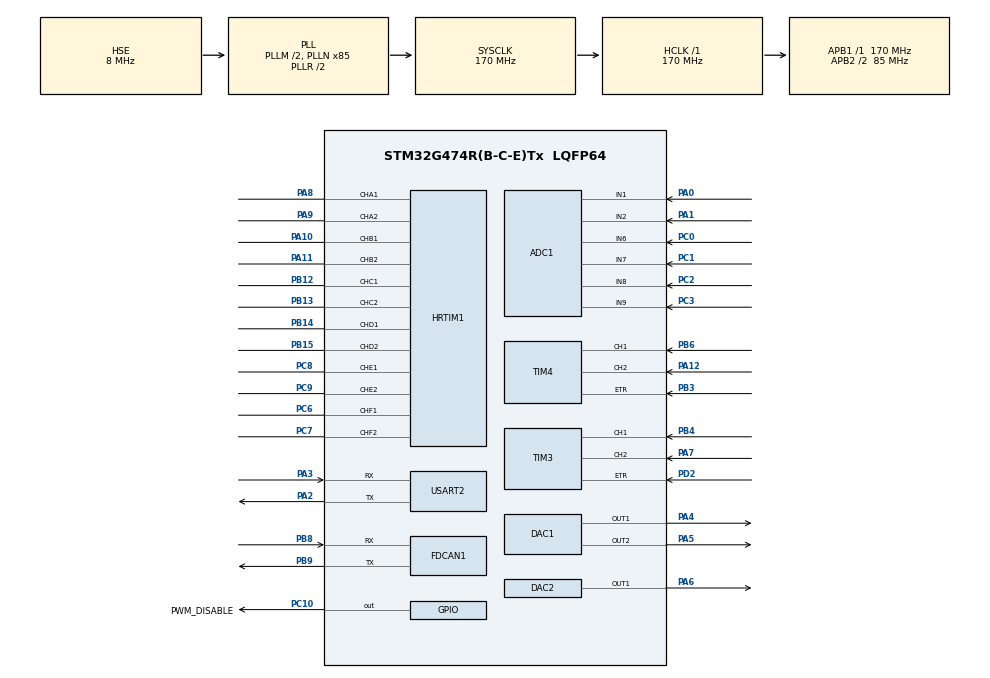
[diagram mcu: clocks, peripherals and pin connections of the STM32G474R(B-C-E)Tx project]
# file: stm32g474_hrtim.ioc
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ADC1.Channel-0\#ChannelRegularConversion=ADC_CHANNEL_6
ADC1.NbrOfConversionFlag=1
ADC1.OffsetNumber-0\#ChannelRegularConversion=ADC_OFFSET_NONE
ADC1.Rank-0\#ChannelRegularConversion=1
ADC1.SamplingTime-0\#ChannelRegularConversion=ADC_SAMPLETIME_2CYCLES_5
ADC1.SingleDiff-0\#ChannelRegularConversion=ADC_DIFFERENTIAL_ENDED
ADC1.master=1
DAC1.DAC_Channel-DAC_OUT2=DAC_CHANNEL_2
Dma.Request0=USART2_RX
Dma.USART2_RX.0.Direction=DMA_PERIPH_TO_MEMORY
Dma.USART2_RX.0.EventEnable=DISABLE
Dma.USART2_RX.0.Instance=DMA1_Channel2
Dma.USART2_RX.0.MemDataAlignment=DMA_MDATAALIGN_BYTE
Dma.USART2_RX.0.MemInc=DMA_MINC_ENABLE
Dma.USART2_RX.0.Mode=DMA_CIRCULAR
Dma.USART2_RX.0.PeriphDataAlignment=DMA_PDATAALIGN_BYTE
Dma.USART2_RX.0.PeriphInc=DMA_PINC_DISABLE
Dma.USART2_RX.0.Polarity=HAL_DMAMUX_REQ_GEN_RISING
Dma.USART2_RX.0.Priority=DMA_PRIORITY_LOW
Dma.USART2_RX.0.RequestNumber=1
Dma.USART2_RX.0.SignalID=NONE
Dma.USART2_RX.0.SyncEnable=DISABLE
Dma.USART2_RX.0.SyncPolarity=HAL_DMAMUX_SYNC_NO_EVENT
Dma.USART2_RX.0.SyncRequestNumber=1
Dma.USART2_RX.0.SyncSignalID=NONE
FDCAN1.CalculateBaudRateNominal=3541666
FDCAN1.CalculateTimeBitNominal=282
FDCAN1.CalculateTimeQuantumNominal=94.11764705882354
HRTIM1.ADCTrigger1_Source1=HRTIM_ADCTRIGGEREVENT13_TIMERA_PERIOD
HRTIM1.ADCTrigger_Id1=HRTIM_ADCTRIGGER_1
HRTIM1.CompareUnit1-Output_TA1TA2=HRTIM_COMPAREUNIT_1
HRTIM1.CompareValue1-Output_TA1TA2=17000
HRTIM1.DeadTimeInsertion-Output_TA1TA2=HRTIM_TIMDEADTIMEINSERTION_ENABLED
HRTIM1.Deadtimeconfig-Output_TA1TA2=HRTIM_TIMERINDEX_TIMER_A
HRTIM1.FallingValue-Output_TA1TA2=85
HRTIM1.NumberADCTriggerSource1=1
HRTIM1.NumberResetSource1-Output_TA1TA2=1
HRTIM1.NumberSetSource1-Output_TA1TA2=1
HRTIM1.Periode_TA=HRTIM_PERIOD
HRTIM1.PreloadEnable-Output_TA1TA2=HRTIM_PRELOAD_ENABLED
HRTIM1.PrescalerDead-Output_TA1TA2=HRTIM_TIMDEADTIME_PRESCALERRATIO_DIV1
HRTIM1.PrescalerRatio_TA=HRTIM_PRESCALERRATIO_MUL8
HRTIM1.ResetOutput1_Source1-Output_TA1TA2=HRTIM_OUTPUTRESET_TIMPER
HRTIM1.RisingValue-Output_TA1TA2=85
HRTIM1.SetOutput1_Source1-Output_TA1TA2=HRTIM_OUTPUTSET_TIMCMP1
HRTIM1.UpDownMode-Output_TA1TA2=HRTIM_TIMERUPDOWNMODE_UPDOWN
Mcu.Family=STM32G4
Mcu.Name=STM32G474R(B-C-E)Tx
Mcu.Package=LQFP64
Mcu.UserConstants=HRTIM_PERIOD,34000
NVIC.ADC1_2_IRQn=true\:0\:0\:false\:false\:true\:true\:true\:true
NVIC.DMA1_Channel2_IRQn=true\:1\:0\:false\:false\:true\:false\:true\:true
NVIC.PriorityGroup=NVIC_PRIORITYGROUP_4
NVIC.USART2_IRQn=true\:1\:0\:false\:false\:true\:true\:true\:true
PA0.Mode=IN1-Differential
PA0.Signal=ADC1_IN1
PA1.Mode=IN1-Differential
PA1.Signal=ADC1_IN2
PA10.Mode=Output_TB1TB2
PA10.Signal=HRTIM1_CHB1
PA11.Mode=Output_TB1TB2
PA11.Signal=HRTIM1_CHB2
PA12.Signal=S_TIM4_CH2
PA13.Mode=Serial_Wire
PA13.Signal=SYS_JTMS-SWDIO
PA14.Mode=Serial_Wire
PA14.Signal=SYS_JTCK-SWCLK
PA2.Mode=Asynchronous
PA2.Signal=USART2_TX
PA3.Mode=Asynchronous
PA3.Signal=USART2_RX
PA4.Signal=COMP_DAC11_group
PA5.Signal=COMP_DAC12_group
PA6.Signal=COMP_DAC21_group
PA7.Signal=S_TIM3_CH2
PA8.Mode=Output_TA1TA2
PA8.Signal=HRTIM1_CHA1
PA9.Mode=Output_TA1TA2
PA9.Signal=HRTIM1_CHA2
PB12.Mode=Output_TC1TC2
PB12.Signal=HRTIM1_CHC1
PB13.Mode=Output_TC1TC2
PB13.Signal=HRTIM1_CHC2
PB14.Mode=Output_TD1TD2
PB14.Signal=HRTIM1_CHD1
PB15.Mode=Output_TD1TD2
PB15.Signal=HRTIM1_CHD2
PB3.Signal=S_TIM4_ETR
PB4.Signal=S_TIM3_CH1
PB6.Signal=S_TIM4_CH1
PB8-BOOT0.Mode=FDCAN_Activate
PB8-BOOT0.Signal=FDCAN1_RX
PB9.Mode=FDCAN_Activate
PB9.Signal=FDCAN1_TX
PC0.Mode=IN6-Differential
PC0.Signal=ADC1_IN6
PC1.Mode=IN6-Differential
PC1.Signal=ADC1_IN7
PC10.GPIO_Label=PWM_DISABLE
PC10.Signal=GPIO_Output
PC14-OSC32_IN.Mode=LSE-External-Oscillator
PC14-OSC32_IN.Signal=RCC_OSC32_IN
PC15-OSC32_OUT.Mode=LSE-External-Oscillator
PC15-OSC32_OUT.Signal=RCC_OSC32_OUT
PC2.Mode=IN8-Differential
PC2.Signal=ADC1_IN8
PC3.Mode=IN8-Differential
PC3.Signal=ADC1_IN9
PC6.Mode=Output_TF1TF2
PC6.Signal=HRTIM1_CHF1
PC7.Mode=Output_TF1TF2
PC7.Signal=HRTIM1_CHF2
PC8.Mode=Output_TE1TE2
PC8.Signal=HRTIM1_CHE1
PC9.Mode=Output_TE1TE2
PC9.Signal=HRTIM1_CHE2
PD2.Signal=S_TIM3_ETR
PF0-OSC_IN.Mode=HSE-External-Oscillator
PF0-OSC_IN.Signal=RCC_OSC_IN
PF1-OSC_OUT.Mode=HSE-External-Oscillator
PF1-OSC_OUT.Signal=RCC_OSC_OUT
ProjectManager.HeapSize=0x200
ProjectManager.StackSize=0x400
ProjectManager.TargetToolchain=MDK-ARM V5.32
RCC.ADC12Freq_Value=170000000
RCC.ADC345Freq_Value=170000000
RCC.AHBFreq_Value=170000000
RCC.APB1Freq_Value=170000000
RCC.APB1TimFreq_Value=170000000
RCC.APB2CLKDivider=RCC_HCLK_DIV2
RCC.APB2Freq_Value=85000000
RCC.APB2TimFreq_Value=170000000
RCC.CortexFreq_Value=170000000
RCC.EXTERNAL_CLOCK_VALUE=12288000
RCC.HCLKFreq_Value=170000000
RCC.HSE_VALUE=8000000
RCC.HSI48_VALUE=48000000
RCC.HSI_VALUE=16000000
RCC.PLLM=RCC_PLLM_DIV2
RCC.PLLN=85
RCC.PLLSourceVirtual=RCC_PLLSOURCE_HSE
RCC.SYSCLKFreq_VALUE=170000000
RCC.SYSCLKSource=RCC_SYSCLKSOURCE_PLLCLK
RCC.USBFreq_Value=170000000
RCC.VCOOutputFreq_Value=340000000
SH.COMP_DAC11_group.0=DAC1_OUT1,DAC_OUT1
SH.COMP_DAC12_group.0=DAC1_OUT2,DAC_OUT2
SH.COMP_DAC21_group.0=DAC2_OUT1,DAC_OUT1
SH.S_TIM3_CH1.0=TIM3_CH1,Encoder_Interface_w_index
SH.S_TIM3_CH2.0=TIM3_CH2,Encoder_Interface_w_index
SH.S_TIM3_ETR.0=TIM3_ETR,Encoder_Interface_w_index
SH.S_TIM4_CH1.0=TIM4_CH1,Encoder_Interface_w_index
SH.S_TIM4_CH2.0=TIM4_CH2,Encoder_Interface_w_index
SH.S_TIM4_ETR.0=TIM4_ETR,Encoder_Interface_w_index
USART2.VirtualMode-Asynchronous=VM_ASYNC
VP_SYS_VS_DBSignals.Mode=DisableDeadBatterySignals
board=custom

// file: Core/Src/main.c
/* USER CODE BEGIN Header */
/**
  ******************************************************************************
  * @file           : main.c
  * @brief          : Main program body
  ******************************************************************************
  * @attention
  *
  * Copyright (c) 2026 STMicroelectronics.
  * All rights reserved.
  *
  * This software is licensed under terms that can be found in the LICENSE file
  * in the root directory of this software component.
  * If no LICENSE file comes with this software, it is provided AS-IS.
  *
  ******************************************************************************
  */
/* USER CODE END Header */
#include "main.h"

/* USER CODE BEGIN Includes */
#include<gmp_core.h>
/* USER CODE END Includes */

ADC_HandleTypeDef hadc1;

DAC_HandleTypeDef hdac1;
DAC_HandleTypeDef hdac2;

FDCAN_HandleTypeDef hfdcan1;

HRTIM_HandleTypeDef hhrtim1;

TIM_HandleTypeDef htim3;
TIM_HandleTypeDef htim4;

UART_HandleTypeDef huart2;
DMA_HandleTypeDef hdma_usart2_rx;

void SystemClock_Config(void);
static void MX_GPIO_Init(void);
static void MX_DAC1_Init(void);
static void MX_DAC2_Init(void);
static void MX_FDCAN1_Init(void);
static void MX_HRTIM1_Init(void);
static void MX_TIM3_Init(void);
static void MX_TIM4_Init(void);
static void MX_USART2_UART_Init(void);
static void MX_ADC1_Init(void);

int main(void)
{

  /* MCU Configuration--------------------------------------------------------*/

  /* Reset of all peripherals, Initializes the Flash interface and the Systick. */
  HAL_Init();

  /* Configure the system clock */
  SystemClock_Config();

  /* Initialize all configured peripherals */
  MX_GPIO_Init();
  MX_DAC1_Init();
  MX_DAC2_Init();
  MX_FDCAN1_Init();
  MX_HRTIM1_Init();
  MX_TIM3_Init();
  MX_TIM4_Init();
  MX_USART2_UART_Init();
  MX_ADC1_Init();

  /* Infinite loop */
  while (1)
  {

  }
}

void SystemClock_Config(void)
{
  RCC_OscInitTypeDef RCC_OscInitStruct = {0};
  RCC_ClkInitTypeDef RCC_ClkInitStruct = {0};

  /** Configure the main internal regulator output voltage
  */
  HAL_PWREx_ControlVoltageScaling(PWR_REGULATOR_VOLTAGE_SCALE1_BOOST);

  /** Initializes the RCC Oscillators according to the specified parameters
  * in the RCC_OscInitTypeDef structure.
  */
  RCC_OscInitStruct.OscillatorType = RCC_OSCILLATORTYPE_HSE;
  RCC_OscInitStruct.HSEState = RCC_HSE_ON;
  RCC_OscInitStruct.PLL.PLLState = RCC_PLL_ON;
  RCC_OscInitStruct.PLL.PLLSource = RCC_PLLSOURCE_HSE;
  RCC_OscInitStruct.PLL.PLLM = RCC_PLLM_DIV2;
  RCC_OscInitStruct.PLL.PLLN = 85;
  RCC_OscInitStruct.PLL.PLLP = RCC_PLLP_DIV2;
  RCC_OscInitStruct.PLL.PLLQ = RCC_PLLQ_DIV2;
  RCC_OscInitStruct.PLL.PLLR = RCC_PLLR_DIV2;
  if (HAL_RCC_OscConfig(&RCC_OscInitStruct) != HAL_OK)
  {
    Error_Handler();
  }

  /** Initializes the CPU, AHB and APB buses clocks
  */
  RCC_ClkInitStruct.ClockType = RCC_CLOCKTYPE_HCLK|RCC_CLOCKTYPE_SYSCLK
                              |RCC_CLOCKTYPE_PCLK1|RCC_CLOCKTYPE_PCLK2;
  RCC_ClkInitStruct.SYSCLKSource = RCC_SYSCLKSOURCE_PLLCLK;
  RCC_ClkInitStruct.AHBCLKDivider = RCC_SYSCLK_DIV1;
  RCC_ClkInitStruct.APB1CLKDivider = RCC_HCLK_DIV1;
  RCC_ClkInitStruct.APB2CLKDivider = RCC_HCLK_DIV2;

  if (HAL_RCC_ClockConfig(&RCC_ClkInitStruct, FLASH_LATENCY_4) != HAL_OK)
  {
    Error_Handler();
  }
}

static void MX_ADC1_Init(void)
{

  ADC_MultiModeTypeDef multimode = {0};
  ADC_ChannelConfTypeDef sConfig = {0};

  /** Common config
  */
  hadc1.Instance = ADC1;
  hadc1.Init.ClockPrescaler = ADC_CLOCK_SYNC_PCLK_DIV4;
  hadc1.Init.Resolution = ADC_RESOLUTION_12B;
  hadc1.Init.DataAlign = ADC_DATAALIGN_RIGHT;
  hadc1.Init.GainCompensation = 0;
  hadc1.Init.ScanConvMode = ADC_SCAN_DISABLE;
  hadc1.Init.EOCSelection = ADC_EOC_SINGLE_CONV;
  hadc1.Init.LowPowerAutoWait = DISABLE;
  hadc1.Init.ContinuousConvMode = DISABLE;
  hadc1.Init.NbrOfConversion = 1;
  hadc1.Init.DiscontinuousConvMode = DISABLE;
  hadc1.Init.ExternalTrigConv = ADC_SOFTWARE_START;
  hadc1.Init.ExternalTrigConvEdge = ADC_EXTERNALTRIGCONVEDGE_NONE;
  hadc1.Init.DMAContinuousRequests = DISABLE;
  hadc1.Init.Overrun = ADC_OVR_DATA_PRESERVED;
  hadc1.Init.OversamplingMode = DISABLE;
  if (HAL_ADC_Init(&hadc1) != HAL_OK)
  {
    Error_Handler();
  }

  /** Configure the ADC multi-mode
  */
  multimode.Mode = ADC_MODE_INDEPENDENT;
  if (HAL_ADCEx_MultiModeConfigChannel(&hadc1, &multimode) != HAL_OK)
  {
    Error_Handler();
  }

  /** Configure Regular Channel
  */
  sConfig.Channel = ADC_CHANNEL_6;
  sConfig.Rank = ADC_REGULAR_RANK_1;
  sConfig.SamplingTime = ADC_SAMPLETIME_2CYCLES_5;
  sConfig.SingleDiff = ADC_DIFFERENTIAL_ENDED;
  sConfig.OffsetNumber = ADC_OFFSET_NONE;
  sConfig.Offset = 0;
  if (HAL_ADC_ConfigChannel(&hadc1, &sConfig) != HAL_OK)
  {
    Error_Handler();
  }

}

static void MX_DAC1_Init(void)
{

  DAC_ChannelConfTypeDef sConfig = {0};

  /** DAC Initialization
  */
  hdac1.Instance = DAC1;
  if (HAL_DAC_Init(&hdac1) != HAL_OK)
  {
    Error_Handler();
  }

  /** DAC channel OUT1 config
  */
  sConfig.DAC_HighFrequency = DAC_HIGH_FREQUENCY_INTERFACE_MODE_AUTOMATIC;
  sConfig.DAC_DMADoubleDataMode = DISABLE;
  sConfig.DAC_SignedFormat = DISABLE;
  sConfig.DAC_SampleAndHold = DAC_SAMPLEANDHOLD_DISABLE;
  sConfig.DAC_Trigger = DAC_TRIGGER_NONE;
  sConfig.DAC_Trigger2 = DAC_TRIGGER_NONE;
  sConfig.DAC_OutputBuffer = DAC_OUTPUTBUFFER_ENABLE;
  sConfig.DAC_ConnectOnChipPeripheral = DAC_CHIPCONNECT_EXTERNAL;
  sConfig.DAC_UserTrimming = DAC_TRIMMING_FACTORY;
  if (HAL_DAC_ConfigChannel(&hdac1, &sConfig, DAC_CHANNEL_1) != HAL_OK)
  {
    Error_Handler();
  }

  /** DAC channel OUT2 config
  */
  if (HAL_DAC_ConfigChannel(&hdac1, &sConfig, DAC_CHANNEL_2) != HAL_OK)
  {
    Error_Handler();
  }

}

static void MX_DAC2_Init(void)
{

  DAC_ChannelConfTypeDef sConfig = {0};

  /** DAC Initialization
  */
  hdac2.Instance = DAC2;
  if (HAL_DAC_Init(&hdac2) != HAL_OK)
  {
    Error_Handler();
  }

  /** DAC channel OUT1 config
  */
  sConfig.DAC_HighFrequency = DAC_HIGH_FREQUENCY_INTERFACE_MODE_AUTOMATIC;
  sConfig.DAC_DMADoubleDataMode = DISABLE;
  sConfig.DAC_SignedFormat = DISABLE;
  sConfig.DAC_SampleAndHold = DAC_SAMPLEANDHOLD_DISABLE;
  sConfig.DAC_Trigger = DAC_TRIGGER_NONE;
  sConfig.DAC_Trigger2 = DAC_TRIGGER_NONE;
  sConfig.DAC_OutputBuffer = DAC_OUTPUTBUFFER_ENABLE;
  sConfig.DAC_ConnectOnChipPeripheral = DAC_CHIPCONNECT_EXTERNAL;
  sConfig.DAC_UserTrimming = DAC_TRIMMING_FACTORY;
  if (HAL_DAC_ConfigChannel(&hdac2, &sConfig, DAC_CHANNEL_1) != HAL_OK)
  {
    Error_Handler();
  }

}

static void MX_FDCAN1_Init(void)
{

  hfdcan1.Instance = FDCAN1;
  hfdcan1.Init.ClockDivider = FDCAN_CLOCK_DIV1;
  hfdcan1.Init.FrameFormat = FDCAN_FRAME_CLASSIC;
  hfdcan1.Init.Mode = FDCAN_MODE_NORMAL;
  hfdcan1.Init.AutoRetransmission = DISABLE;
  hfdcan1.Init.TransmitPause = DISABLE;
  hfdcan1.Init.ProtocolException = DISABLE;
  hfdcan1.Init.NominalPrescaler = 16;
  hfdcan1.Init.NominalSyncJumpWidth = 1;
  hfdcan1.Init.NominalTimeSeg1 = 1;
  hfdcan1.Init.NominalTimeSeg2 = 1;
  hfdcan1.Init.DataPrescaler = 1;
  hfdcan1.Init.DataSyncJumpWidth = 1;
  hfdcan1.Init.DataTimeSeg1 = 1;
  hfdcan1.Init.DataTimeSeg2 = 1;
  hfdcan1.Init.StdFiltersNbr = 0;
  hfdcan1.Init.ExtFiltersNbr = 0;
  hfdcan1.Init.TxFifoQueueMode = FDCAN_TX_FIFO_OPERATION;
  if (HAL_FDCAN_Init(&hfdcan1) != HAL_OK)
  {
    Error_Handler();
  }

}

static void MX_HRTIM1_Init(void)
{

  HRTIM_ADCTriggerCfgTypeDef pADCTriggerCfg = {0};
  HRTIM_TimeBaseCfgTypeDef pTimeBaseCfg = {0};
  HRTIM_TimerCtlTypeDef pTimerCtl = {0};
  HRTIM_TimerCfgTypeDef pTimerCfg = {0};
  HRTIM_CompareCfgTypeDef pCompareCfg = {0};
  HRTIM_DeadTimeCfgTypeDef pDeadTimeCfg = {0};
  HRTIM_OutputCfgTypeDef pOutputCfg = {0};

  hhrtim1.Instance = HRTIM1;
  hhrtim1.Init.HRTIMInterruptResquests = HRTIM_IT_NONE;
  hhrtim1.Init.SyncOptions = HRTIM_SYNCOPTION_NONE;
  if (HAL_HRTIM_Init(&hhrtim1) != HAL_OK)
  {
    Error_Handler();
  }
  if (HAL_HRTIM_DLLCalibrationStart(&hhrtim1, HRTIM_CALIBRATIONRATE_3) != HAL_OK)
  {
    Error_Handler();
  }
  if (HAL_HRTIM_PollForDLLCalibration(&hhrtim1, 10) != HAL_OK)
  {
    Error_Handler();
  }
  pADCTriggerCfg.UpdateSource = HRTIM_ADCTRIGGERUPDATE_TIMER_A;
  pADCTriggerCfg.Trigger = HRTIM_ADCTRIGGEREVENT13_TIMERA_PERIOD;
  if (HAL_HRTIM_ADCTriggerConfig(&hhrtim1, HRTIM_ADCTRIGGER_1, &pADCTriggerCfg) != HAL_OK)
  {
    Error_Handler();
  }
  if (HAL_HRTIM_ADCPostScalerConfig(&hhrtim1, HRTIM_ADCTRIGGER_1, 0x0) != HAL_OK)
  {
    Error_Handler();
  }
  pTimeBaseCfg.Period = HRTIM_PERIOD;
  pTimeBaseCfg.RepetitionCounter = 0x00;
  pTimeBaseCfg.PrescalerRatio = HRTIM_PRESCALERRATIO_MUL8;
  pTimeBaseCfg.Mode = HRTIM_MODE_CONTINUOUS;
  if (HAL_HRTIM_TimeBaseConfig(&hhrtim1, HRTIM_TIMERINDEX_TIMER_A, &pTimeBaseCfg) != HAL_OK)
  {
    Error_Handler();
  }
  pTimerCtl.UpDownMode = HRTIM_TIMERUPDOWNMODE_UPDOWN;
  pTimerCtl.GreaterCMP1 = HRTIM_TIMERGTCMP1_EQUAL;
  pTimerCtl.DualChannelDacEnable = HRTIM_TIMER_DCDE_DISABLED;
  if (HAL_HRTIM_WaveformTimerControl(&hhrtim1, HRTIM_TIMERINDEX_TIMER_A, &pTimerCtl) != HAL_OK)
  {
    Error_Handler();
  }
  if (HAL_HRTIM_RollOverModeConfig(&hhrtim1, HRTIM_TIMERINDEX_TIMER_A, HRTIM_TIM_FEROM_BOTH|HRTIM_TIM_BMROM_BOTH
                              |HRTIM_TIM_ADROM_BOTH|HRTIM_TIM_OUTROM_BOTH
                              |HRTIM_TIM_ROM_BOTH) != HAL_OK)
  {
    Error_Handler();
  }
  pTimerCfg.InterruptRequests = HRTIM_TIM_IT_NONE;
  pTimerCfg.DMARequests = HRTIM_TIM_DMA_NONE;
  pTimerCfg.DMASrcAddress = 0x0000;
  pTimerCfg.DMADstAddress = 0x0000;
  pTimerCfg.DMASize = 0x1;
  pTimerCfg.HalfModeEnable = HRTIM_HALFMODE_DISABLED;
  pTimerCfg.InterleavedMode = HRTIM_INTERLEAVED_MODE_DISABLED;
  pTimerCfg.StartOnSync = HRTIM_SYNCSTART_DISABLED;
  pTimerCfg.ResetOnSync = HRTIM_SYNCRESET_DISABLED;
  pTimerCfg.DACSynchro = HRTIM_DACSYNC_NONE;
  pTimerCfg.PreloadEnable = HRTIM_PRELOAD_ENABLED;
  pTimerCfg.UpdateGating = HRTIM_UPDATEGATING_INDEPENDENT;
  pTimerCfg.BurstMode = HRTIM_TIMERBURSTMODE_MAINTAINCLOCK;
  pTimerCfg.RepetitionUpdate = HRTIM_UPDATEONREPETITION_DISABLED;
  pTimerCfg.PushPull = HRTIM_TIMPUSHPULLMODE_DISABLED;
  pTimerCfg.FaultEnable = HRTIM_TIMFAULTENABLE_NONE;
  pTimerCfg.FaultLock = HRTIM_TIMFAULTLOCK_READWRITE;
  pTimerCfg.DeadTimeInsertion = HRTIM_TIMDEADTIMEINSERTION_ENABLED;
  pTimerCfg.DelayedProtectionMode = HRTIM_TIMER_A_B_C_DELAYEDPROTECTION_DISABLED;
  pTimerCfg.UpdateTrigger = HRTIM_TIMUPDATETRIGGER_NONE;
  pTimerCfg.ResetTrigger = HRTIM_TIMRESETTRIGGER_NONE;
  pTimerCfg.ResetUpdate = HRTIM_TIMUPDATEONRESET_DISABLED;
  pTimerCfg.ReSyncUpdate = HRTIM_TIMERESYNC_UPDATE_UNCONDITIONAL;
  if (HAL_HRTIM_WaveformTimerConfig(&hhrtim1, HRTIM_TIMERINDEX_TIMER_A, &pTimerCfg) != HAL_OK)
  {
    Error_Handler();
  }
  pTimerCfg.PreloadEnable = HRTIM_PRELOAD_DISABLED;
  pTimerCfg.DeadTimeInsertion = HRTIM_TIMDEADTIMEINSERTION_DISABLED;
  if (HAL_HRTIM_WaveformTimerConfig(&hhrtim1, HRTIM_TIMERINDEX_TIMER_B, &pTimerCfg) != HAL_OK)
  {
    Error_Handler();
  }
  if (HAL_HRTIM_WaveformTimerConfig(&hhrtim1, HRTIM_TIMERINDEX_TIMER_C, &pTimerCfg) != HAL_OK)
  {
    Error_Handler();
  }
  pTimerCfg.DelayedProtectionMode = HRTIM_TIMER_D_E_DELAYEDPROTECTION_DISABLED;
  if (HAL_HRTIM_WaveformTimerConfig(&hhrtim1, HRTIM_TIMERINDEX_TIMER_D, &pTimerCfg) != HAL_OK)
  {
    Error_Handler();
  }
  if (HAL_HRTIM_WaveformTimerConfig(&hhrtim1, HRTIM_TIMERINDEX_TIMER_E, &pTimerCfg) != HAL_OK)
  {
    Error_Handler();
  }
  pTimerCfg.DelayedProtectionMode = HRTIM_TIMER_F_DELAYEDPROTECTION_DISABLED;
  if (HAL_HRTIM_WaveformTimerConfig(&hhrtim1, HRTIM_TIMERINDEX_TIMER_F, &pTimerCfg) != HAL_OK)
  {
    Error_Handler();
  }
  pCompareCfg.CompareValue = 17000;
  if (HAL_HRTIM_WaveformCompareConfig(&hhrtim1, HRTIM_TIMERINDEX_TIMER_A, HRTIM_COMPAREUNIT_1, &pCompareCfg) != HAL_OK)
  {
    Error_Handler();
  }
  pDeadTimeCfg.Prescaler = HRTIM_TIMDEADTIME_PRESCALERRATIO_DIV1;
  pDeadTimeCfg.RisingValue = 85;
  pDeadTimeCfg.RisingSign = HRTIM_TIMDEADTIME_RISINGSIGN_POSITIVE;
  pDeadTimeCfg.RisingLock = HRTIM_TIMDEADTIME_RISINGLOCK_WRITE;
  pDeadTimeCfg.RisingSignLock = HRTIM_TIMDEADTIME_RISINGSIGNLOCK_WRITE;
  pDeadTimeCfg.FallingValue = 85;
  pDeadTimeCfg.FallingSign = HRTIM_TIMDEADTIME_FALLINGSIGN_POSITIVE;
  pDeadTimeCfg.FallingLock = HRTIM_TIMDEADTIME_FALLINGLOCK_WRITE;
  pDeadTimeCfg.FallingSignLock = HRTIM_TIMDEADTIME_FALLINGSIGNLOCK_WRITE;
  if (HAL_HRTIM_DeadTimeConfig(&hhrtim1, HRTIM_TIMERINDEX_TIMER_A, &pDeadTimeCfg) != HAL_OK)
  {
    Error_Handler();
  }
  pOutputCfg.Polarity = HRTIM_OUTPUTPOLARITY_HIGH;
  pOutputCfg.SetSource = HRTIM_OUTPUTSET_TIMCMP1;
  pOutputCfg.ResetSource = HRTIM_OUTPUTRESET_TIMPER;
  pOutputCfg.IdleMode = HRTIM_OUTPUTIDLEMODE_NONE;
  pOutputCfg.IdleLevel = HRTIM_OUTPUTIDLELEVEL_INACTIVE;
  pOutputCfg.FaultLevel = HRTIM_OUTPUTFAULTLEVEL_NONE;
  pOutputCfg.ChopperModeEnable = HRTIM_OUTPUTCHOPPERMODE_DISABLED;
  pOutputCfg.BurstModeEntryDelayed = HRTIM_OUTPUTBURSTMODEENTRY_REGULAR;
  if (HAL_HRTIM_WaveformOutputConfig(&hhrtim1, HRTIM_TIMERINDEX_TIMER_A, HRTIM_OUTPUT_TA1, &pOutputCfg) != HAL_OK)
  {
    Error_Handler();
  }
  pOutputCfg.SetSource = HRTIM_OUTPUTSET_NONE;
  pOutputCfg.ResetSource = HRTIM_OUTPUTRESET_NONE;
  if (HAL_HRTIM_WaveformOutputConfig(&hhrtim1, HRTIM_TIMERINDEX_TIMER_B, HRTIM_OUTPUT_TB1, &pOutputCfg) != HAL_OK)
  {
    Error_Handler();
  }
  if (HAL_HRTIM_WaveformOutputConfig(&hhrtim1, HRTIM_TIMERINDEX_TIMER_C, HRTIM_OUTPUT_TC1, &pOutputCfg) != HAL_OK)
  {
    Error_Handler();
  }
  if (HAL_HRTIM_WaveformOutputConfig(&hhrtim1, HRTIM_TIMERINDEX_TIMER_D, HRTIM_OUTPUT_TD1, &pOutputCfg) != HAL_OK)
  {
    Error_Handler();
  }
  if (HAL_HRTIM_WaveformOutputConfig(&hhrtim1, HRTIM_TIMERINDEX_TIMER_E, HRTIM_OUTPUT_TE1, &pOutputCfg) != HAL_OK)
  {
    Error_Handler();
  }
  if (HAL_HRTIM_WaveformOutputConfig(&hhrtim1, HRTIM_TIMERINDEX_TIMER_F, HRTIM_OUTPUT_TF1, &pOutputCfg) != HAL_OK)
  {
    Error_Handler();
  }
  if (HAL_HRTIM_WaveformOutputConfig(&hhrtim1, HRTIM_TIMERINDEX_TIMER_A, HRTIM_OUTPUT_TA2, &pOutputCfg) != HAL_OK)
  {
    Error_Handler();
  }
  if (HAL_HRTIM_WaveformOutputConfig(&hhrtim1, HRTIM_TIMERINDEX_TIMER_B, HRTIM_OUTPUT_TB2, &pOutputCfg) != HAL_OK)
  {
    Error_Handler();
  }
  if (HAL_HRTIM_WaveformOutputConfig(&hhrtim1, HRTIM_TIMERINDEX_TIMER_C, HRTIM_OUTPUT_TC2, &pOutputCfg) != HAL_OK)
  {
    Error_Handler();
  }
  if (HAL_HRTIM_WaveformOutputConfig(&hhrtim1, HRTIM_TIMERINDEX_TIMER_D, HRTIM_OUTPUT_TD2, &pOutputCfg) != HAL_OK)
  {
    Error_Handler();
  }
  if (HAL_HRTIM_WaveformOutputConfig(&hhrtim1, HRTIM_TIMERINDEX_TIMER_E, HRTIM_OUTPUT_TE2, &pOutputCfg) != HAL_OK)
  {
    Error_Handler();
  }
  if (HAL_HRTIM_WaveformOutputConfig(&hhrtim1, HRTIM_TIMERINDEX_TIMER_F, HRTIM_OUTPUT_TF2, &pOutputCfg) != HAL_OK)
  {
    Error_Handler();
  }
  pTimeBaseCfg.Period = 0xFFDF;
  pTimeBaseCfg.PrescalerRatio = HRTIM_PRESCALERRATIO_MUL32;
  if (HAL_HRTIM_TimeBaseConfig(&hhrtim1, HRTIM_TIMERINDEX_TIMER_B, &pTimeBaseCfg) != HAL_OK)
  {
    Error_Handler();
  }
  pTimerCtl.UpDownMode = HRTIM_TIMERUPDOWNMODE_UP;
  if (HAL_HRTIM_WaveformTimerControl(&hhrtim1, HRTIM_TIMERINDEX_TIMER_B, &pTimerCtl) != HAL_OK)
  {
    Error_Handler();
  }
  if (HAL_HRTIM_TimeBaseConfig(&hhrtim1, HRTIM_TIMERINDEX_TIMER_C, &pTimeBaseCfg) != HAL_OK)
  {
    Error_Handler();
  }
  if (HAL_HRTIM_WaveformTimerControl(&hhrtim1, HRTIM_TIMERINDEX_TIMER_C, &pTimerCtl) != HAL_OK)
  {
    Error_Handler();
  }
  if (HAL_HRTIM_TimeBaseConfig(&hhrtim1, HRTIM_TIMERINDEX_TIMER_D, &pTimeBaseCfg) != HAL_OK)
  {
    Error_Handler();
  }
  if (HAL_HRTIM_WaveformTimerControl(&hhrtim1, HRTIM_TIMERINDEX_TIMER_D, &pTimerCtl) != HAL_OK)
  {
    Error_Handler();
  }
  if (HAL_HRTIM_TimeBaseConfig(&hhrtim1, HRTIM_TIMERINDEX_TIMER_E, &pTimeBaseCfg) != HAL_OK)
  {
    Error_Handler();
  }
  if (HAL_HRTIM_WaveformTimerControl(&hhrtim1, HRTIM_TIMERINDEX_TIMER_E, &pTimerCtl) != HAL_OK)
  {
    Error_Handler();
  }
  if (HAL_HRTIM_TimeBaseConfig(&hhrtim1, HRTIM_TIMERINDEX_TIMER_F, &pTimeBaseCfg) != HAL_OK)
  {
    Error_Handler();
  }
  if (HAL_HRTIM_WaveformTimerControl(&hhrtim1, HRTIM_TIMERINDEX_TIMER_F, &pTimerCtl) != HAL_OK)
  {
    Error_Handler();
  }
  HAL_HRTIM_MspPostInit(&hhrtim1);

}

static void MX_TIM3_Init(void)
{

  TIM_Encoder_InitTypeDef sConfig = {0};
  TIM_MasterConfigTypeDef sMasterConfig = {0};
  TIMEx_EncoderIndexConfigTypeDef sEncoderIndexConfig = {0};

  htim3.Instance = TIM3;
  htim3.Init.Prescaler = 0;
  htim3.Init.CounterMode = TIM_COUNTERMODE_UP;
  htim3.Init.Period = 65535;
  htim3.Init.ClockDivision = TIM_CLOCKDIVISION_DIV1;
  htim3.Init.AutoReloadPreload = TIM_AUTORELOAD_PRELOAD_DISABLE;
  sConfig.EncoderMode = TIM_ENCODERMODE_TI1;
  sConfig.IC1Polarity = TIM_ICPOLARITY_RISING;
  sConfig.IC1Selection = TIM_ICSELECTION_DIRECTTI;
  sConfig.IC1Prescaler = TIM_ICPSC_DIV1;
  sConfig.IC1Filter = 0;
  sConfig.IC2Polarity = TIM_ICPOLARITY_RISING;
  sConfig.IC2Selection = TIM_ICSELECTION_DIRECTTI;
  sConfig.IC2Prescaler = TIM_ICPSC_DIV1;
  sConfig.IC2Filter = 0;
  if (HAL_TIM_Encoder_Init(&htim3, &sConfig) != HAL_OK)
  {
    Error_Handler();
  }
  sMasterConfig.MasterOutputTrigger = TIM_TRGO_RESET;
  sMasterConfig.MasterSlaveMode = TIM_MASTERSLAVEMODE_DISABLE;
  if (HAL_TIMEx_MasterConfigSynchronization(&htim3, &sMasterConfig) != HAL_OK)
  {
    Error_Handler();
  }
  sEncoderIndexConfig.Polarity = TIM_ENCODERINDEX_POLARITY_NONINVERTED;
  sEncoderIndexConfig.Prescaler = TIM_ENCODERINDEX_PRESCALER_DIV1;
  sEncoderIndexConfig.Filter = 0;
  sEncoderIndexConfig.FirstIndexEnable = DISABLE;
  sEncoderIndexConfig.Position = TIM_ENCODERINDEX_POSITION_00;
  sEncoderIndexConfig.Direction = TIM_ENCODERINDEX_DIRECTION_UP_DOWN;
  if (HAL_TIMEx_ConfigEncoderIndex(&htim3, &sEncoderIndexConfig) != HAL_OK)
  {
    Error_Handler();
  }

}

static void MX_TIM4_Init(void)
{

  TIM_Encoder_InitTypeDef sConfig = {0};
  TIM_MasterConfigTypeDef sMasterConfig = {0};
  TIMEx_EncoderIndexConfigTypeDef sEncoderIndexConfig = {0};

  htim4.Instance = TIM4;
  htim4.Init.Prescaler = 0;
  htim4.Init.CounterMode = TIM_COUNTERMODE_UP;
  htim4.Init.Period = 65535;
  htim4.Init.ClockDivision = TIM_CLOCKDIVISION_DIV1;
  htim4.Init.AutoReloadPreload = TIM_AUTORELOAD_PRELOAD_DISABLE;
  sConfig.EncoderMode = TIM_ENCODERMODE_TI1;
  sConfig.IC1Polarity = TIM_ICPOLARITY_RISING;
  sConfig.IC1Selection = TIM_ICSELECTION_DIRECTTI;
  sConfig.IC1Prescaler = TIM_ICPSC_DIV1;
  sConfig.IC1Filter = 0;
  sConfig.IC2Polarity = TIM_ICPOLARITY_RISING;
  sConfig.IC2Selection = TIM_ICSELECTION_DIRECTTI;
  sConfig.IC2Prescaler = TIM_ICPSC_DIV1;
  sConfig.IC2Filter = 0;
  if (HAL_TIM_Encoder_Init(&htim4, &sConfig) != HAL_OK)
  {
    Error_Handler();
  }
  sMasterConfig.MasterOutputTrigger = TIM_TRGO_RESET;
  sMasterConfig.MasterSlaveMode = TIM_MASTERSLAVEMODE_DISABLE;
  if (HAL_TIMEx_MasterConfigSynchronization(&htim4, &sMasterConfig) != HAL_OK)
  {
    Error_Handler();
  }
  sEncoderIndexConfig.Polarity = TIM_ENCODERINDEX_POLARITY_NONINVERTED;
  sEncoderIndexConfig.Prescaler = TIM_ENCODERINDEX_PRESCALER_DIV1;
  sEncoderIndexConfig.Filter = 0;
  sEncoderIndexConfig.FirstIndexEnable = DISABLE;
  sEncoderIndexConfig.Position = TIM_ENCODERINDEX_POSITION_00;
  sEncoderIndexConfig.Direction = TIM_ENCODERINDEX_DIRECTION_UP_DOWN;
  if (HAL_TIMEx_ConfigEncoderIndex(&htim4, &sEncoderIndexConfig) != HAL_OK)
  {
    Error_Handler();
  }

}

static void MX_USART2_UART_Init(void)
{

  huart2.Instance = USART2;
  huart2.Init.BaudRate = 115200;
  huart2.Init.WordLength = UART_WORDLENGTH_8B;
  huart2.Init.StopBits = UART_STOPBITS_1;
  huart2.Init.Parity = UART_PARITY_NONE;
  huart2.Init.Mode = UART_MODE_TX_RX;
  huart2.Init.HwFlowCtl = UART_HWCONTROL_NONE;
  huart2.Init.OverSampling = UART_OVERSAMPLING_16;
  huart2.Init.OneBitSampling = UART_ONE_BIT_SAMPLE_DISABLE;
  huart2.Init.ClockPrescaler = UART_PRESCALER_DIV1;
  huart2.AdvancedInit.AdvFeatureInit = UART_ADVFEATURE_NO_INIT;
  if (HAL_UART_Init(&huart2) != HAL_OK)
  {
    Error_Handler();
  }
  if (HAL_UARTEx_SetTxFifoThreshold(&huart2, UART_TXFIFO_THRESHOLD_1_8) != HAL_OK)
  {
    Error_Handler();
  }
  if (HAL_UARTEx_SetRxFifoThreshold(&huart2, UART_RXFIFO_THRESHOLD_1_8) != HAL_OK)
  {
    Error_Handler();
  }
  if (HAL_UARTEx_DisableFifoMode(&huart2) != HAL_OK)
  {
    Error_Handler();
  }

}

static void MX_GPIO_Init(void)
{
  GPIO_InitTypeDef GPIO_InitStruct = {0};

  /* GPIO Ports Clock Enable */
  __HAL_RCC_GPIOC_CLK_ENABLE();
  __HAL_RCC_GPIOF_CLK_ENABLE();
  __HAL_RCC_GPIOA_CLK_ENABLE();
  __HAL_RCC_GPIOB_CLK_ENABLE();
  __HAL_RCC_GPIOD_CLK_ENABLE();

  /*Configure GPIO pin Output Level */
  HAL_GPIO_WritePin(PWM_DISABLE_GPIO_Port, PWM_DISABLE_Pin, GPIO_PIN_RESET);

  /*Configure GPIO pin : PWM_DISABLE_Pin */
  GPIO_InitStruct.Pin = PWM_DISABLE_Pin;
  GPIO_InitStruct.Mode = GPIO_MODE_OUTPUT_PP;
  GPIO_InitStruct.Pull = GPIO_NOPULL;
  GPIO_InitStruct.Speed = GPIO_SPEED_FREQ_LOW;
  HAL_GPIO_Init(PWM_DISABLE_GPIO_Port, &GPIO_InitStruct);

}

void Error_Handler(void)
{
  __disable_irq();
  while (1)
  {
  }
}
